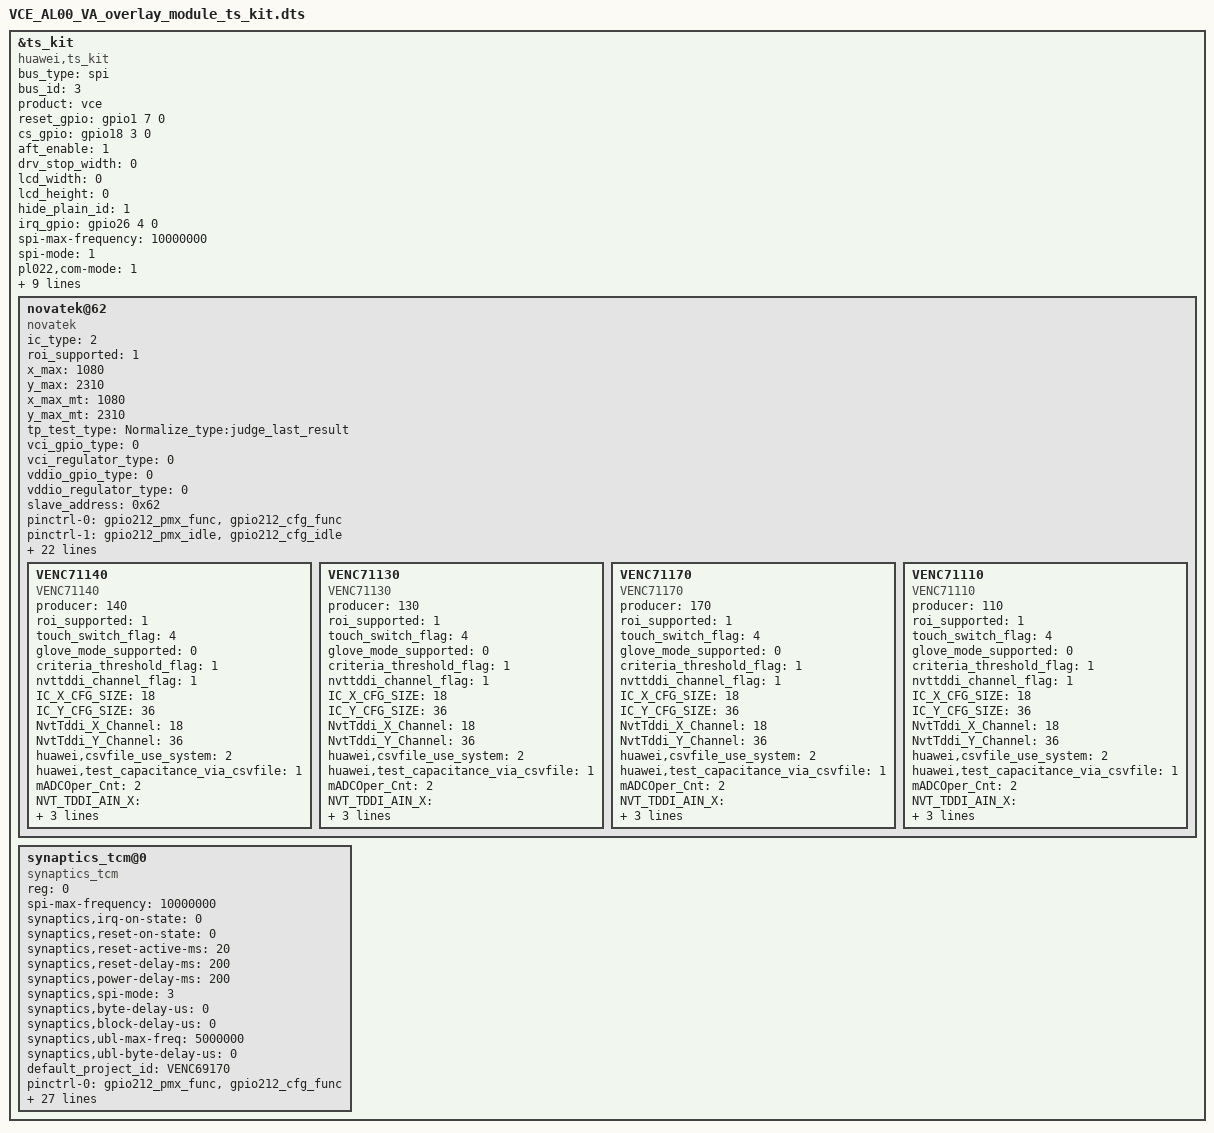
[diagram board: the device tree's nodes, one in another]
/*touch_panel*/
	&ts_kit {
		compatible = "huawei,ts_kit";
		bus_type = "spi";
		bus_id = <3>;
		product = "vce";
		reset_gpio = <&gpio1 7 0>;
		cs_gpio = <&gpio18 3 0>;
		aft_enable = <1>;
		drv_stop_width = <0>;
		lcd_width = <0>;
		lcd_height = <0>;
		hide_plain_id = <1>;
		irq_gpio = <&gpio26 4 0>;
		spi-max-frequency = <10000000>;
		spi-mode = <1>;
		pl022,com-mode = <1>;
		pl022,interface = <0>;
		pl022,rx-level-trig = <3>;
		pl022,tx-level-trig = <3>;
		pl022,ctrl-len = <7>;
		pl022,wait-state = <0>;
		pl022,duplex = <0>;
		pl022,slave-tx-disable = <0>;
		cs_reset_low_delay = <10>;
		cs_reset_high_delay = <200>;
		novatek@62{
			compatible = "novatek";
			ic_type = <2>;
			roi_supported = <1>;
			x_max = <1080>;
			y_max = <2310>;
			x_max_mt = <1080>;
			y_max_mt = <2310>;
			tp_test_type = "Normalize_type:judge_last_result";
			vci_gpio_type = <0>;
			vci_regulator_type = <0>;
			vddio_gpio_type = <0>;
			vddio_regulator_type = <0>;
			slave_address = <0x62>;
			pinctrl-names = "default", "idle";
			pinctrl-0 = <&gpio212_pmx_func &gpio212_cfg_func>;
			pinctrl-1 = <&gpio212_pmx_idle &gpio212_cfg_idle>;
			novatek-vdd-supply;
			novatec-io-supply;
			irq_config = <3>;
			algo_id = <1>;
			noise_test_frame = <30>;
			open_test_by_fw = <1>;
			i2c_retry_time = <50>;
			support_aft = <1>;
			wx_support = <1>;
			glove_mode_supported = <0>;
			nvttddi_channel_flag=<1>;
			default_projectid = "VENC71140";
			use_dma_download_firmware = <1>;
			use_pinctrl=<1>;
			power_sleep_mode = <1>;
			rawdate_pointer_to_pointer = <1>;
			charger_supported = <1>;
			tp_status_report_support = <1>;
			report_priority = <0 3 8 7 12 0xFF 0xFF 0xFF 0xFF 0xFF 0xFF 0xFF 0xFF 0xFF 0xFF 0xFF>;
			report_priority_limite = <50 20 20 50 50 50 50 50 50 50 50 50 50 50 50 50>;/* max is 50, this num is one-to-one mapping report_priority */
			VENC71140 {
				producer = "140";
				compatible = "VENC71140";
				roi_supported = <1>;
				touch_switch_flag = <4>;
				glove_mode_supported = <0>;
				criteria_threshold_flag = <1>;
				nvttddi_channel_flag=<1>;
				IC_X_CFG_SIZE = <18>;
				IC_Y_CFG_SIZE = <36>;
				NvtTddi_X_Channel = <18>;
				NvtTddi_Y_Channel = <36>;
				huawei,csvfile_use_system = <2>;
				huawei,test_capacitance_via_csvfile = <1>;
				mADCOper_Cnt = <2>;
				NVT_TDDI_AIN_X = <0 1 2 3 4 5 6 7 8 9 10 11 12 13 14 15 16 17>;
				NVT_TDDI_AIN_Y = <0 1 2 3 4 5 6 7 8 9 10 11 12 13 14 15 16 17
									18 19 20 21 22 23 24 25 26 27 28 29 30 31 32 33 34 35>;
			};
			VENC71130 {
				producer = "130";
				compatible = "VENC71130";
				roi_supported = <1>;
				touch_switch_flag = <4>;
				glove_mode_supported = <0>;
				criteria_threshold_flag = <1>;
				nvttddi_channel_flag=<1>;
				IC_X_CFG_SIZE = <18>;
				IC_Y_CFG_SIZE = <36>;
				NvtTddi_X_Channel = <18>;
				NvtTddi_Y_Channel = <36>;
				huawei,csvfile_use_system = <2>;
				huawei,test_capacitance_via_csvfile = <1>;
				mADCOper_Cnt = <2>;
				NVT_TDDI_AIN_X = <0 1 2 3 4 5 6 7 8 9 10 11 12 13 14 15 16 17>;
				NVT_TDDI_AIN_Y = <0 1 2 3 4 5 6 7 8 9 10 11 12 13 14 15 16 17
									18 19 20 21 22 23 24 25 26 27 28 29 30 31 32 33 34 35>;
			};
			VENC71170 {
				producer = "170";
				compatible = "VENC71170";
				roi_supported = <1>;
				touch_switch_flag = <4>;
				glove_mode_supported = <0>;
				criteria_threshold_flag = <1>;
				nvttddi_channel_flag=<1>;
				IC_X_CFG_SIZE = <18>;
				IC_Y_CFG_SIZE = <36>;
				NvtTddi_X_Channel = <18>;
				NvtTddi_Y_Channel = <36>;
				huawei,csvfile_use_system = <2>;
				huawei,test_capacitance_via_csvfile = <1>;
				mADCOper_Cnt = <2>;
				NVT_TDDI_AIN_X = <0 1 2 3 4 5 6 7 8 9 10 11 12 13 14 15 16 17>;
				NVT_TDDI_AIN_Y = <0 1 2 3 4 5 6 7 8 9 10 11 12 13 14 15 16 17
									18 19 20 21 22 23 24 25 26 27 28 29 30 31 32 33 34 35>;
			};
			VENC71110 {
				producer = "110";
				compatible = "VENC71110";
				roi_supported = <1>;
				touch_switch_flag = <4>;
				glove_mode_supported = <0>;
				criteria_threshold_flag = <1>;
				nvttddi_channel_flag=<1>;
				IC_X_CFG_SIZE = <18>;
				IC_Y_CFG_SIZE = <36>;
				NvtTddi_X_Channel = <18>;
				NvtTddi_Y_Channel = <36>;
				huawei,csvfile_use_system = <2>;
				huawei,test_capacitance_via_csvfile = <1>;
				mADCOper_Cnt = <2>;
				NVT_TDDI_AIN_X = <0 1 2 3 4 5 6 7 8 9 10 11 12 13 14 15 16 17>;
				NVT_TDDI_AIN_Y = <0 1 2 3 4 5 6 7 8 9 10 11 12 13 14 15 16 17
									18 19 20 21 22 23 24 25 26 27 28 29 30 31 32 33 34 35>;
			};

		};
		synaptics_tcm@0 {
			compatible = "synaptics_tcm";
			reg = <0>;
			spi-max-frequency = <10000000>;
			synaptics,irq-on-state = <0>;
			synaptics,reset-on-state = <0>;
			synaptics,reset-active-ms = <20>;
			synaptics,reset-delay-ms = <200>;
			synaptics,power-delay-ms = <200>;
			synaptics,spi-mode = <3>;
			synaptics,byte-delay-us = <0>;
			synaptics,block-delay-us = <0>;
			synaptics,ubl-max-freq = <5000000>;
			synaptics,ubl-byte-delay-us = <0>;
			default_project_id = "VENC69170";
			pinctrl-names = "default", "idle";
			pinctrl-0 = <&gpio212_pmx_func &gpio212_cfg_func>;
			pinctrl-1 = <&gpio212_pmx_idle &gpio212_cfg_idle>;
			ic_type = <6>;
			irq_config = <0>;
			vci_gpio_type = <0>;
			vci_regulator_type = <0>;
			vddio_gpio_type = <0>;
			vddio_regulator_type = <0>;
			x_max = <1080>;
			y_max = <2310>;
			x_max_mt = <1080>;
			y_max_mt = <2310>;
			use_pinctrl = <1>;
			max_finger_objects = <10>;
			rawdata_newformatflag = <1>;
			roi_supported = <1>;
			glove_supported = <0>;
			charger_supported = <1>;
			aft_wxy_enable = <1>;
			touch_switch_flag = <4>; // 1-doze 2-game 4-scene
			use_dma_download_firmware = <1>;
			downmload_firmware_frequency = <8000000>;
			use_esd_report = <1>;
			tp_status_report_support = <1>;
			report_priority = <0 3 8 7 12 0xFF 0xFF 0xFF 0xFF 0xFF 0xFF 0xFF 0xFF 0xFF 0xFF 0xFF>;
			report_priority_limite = <50 20 20 50 50 50 50 50 50 50 50 50 50 50 50 50>;/* max is 50, this num is one-to-one mapping report_priority */
		};
	};
